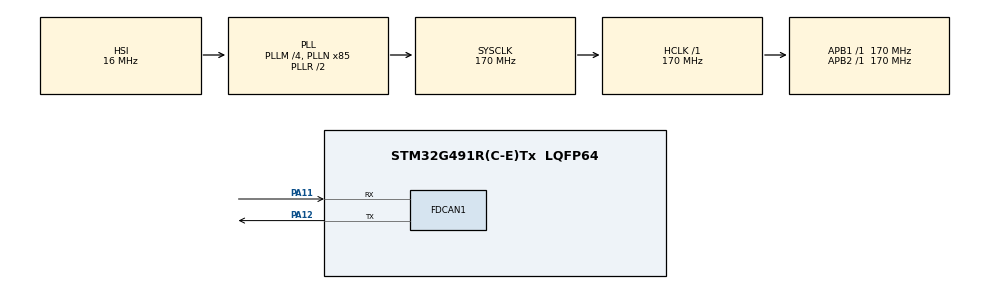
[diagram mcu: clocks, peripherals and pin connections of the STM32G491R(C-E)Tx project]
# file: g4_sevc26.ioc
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FDCAN1.AutoRetransmission=ENABLE
FDCAN1.CalculateBaudRateNominal=500000
FDCAN1.CalculateTimeBitNominal=2000
FDCAN1.CalculateTimeQuantumNominal=100.0
FDCAN1.FrameFormat=FDCAN_FRAME_CLASSIC
FDCAN1.NominalPrescaler=17
FDCAN1.NominalSyncJumpWidth=4
FDCAN1.NominalTimeSeg1=15
FDCAN1.NominalTimeSeg2=4
FDCAN1.StdFiltersNbr=1
Mcu.Family=STM32G4
Mcu.Name=STM32G491R(C-E)Tx
Mcu.Package=LQFP64
NVIC.FDCAN1_IT0_IRQn=true\:0\:0\:false\:false\:true\:true\:true\:true
NVIC.PriorityGroup=NVIC_PRIORITYGROUP_4
PA11.Mode=FDCAN_Activate
PA11.Signal=FDCAN1_RX
PA12.Mode=FDCAN_Activate
PA12.Signal=FDCAN1_TX
ProjectManager.HeapSize=0x200
ProjectManager.StackSize=0x400
ProjectManager.TargetToolchain=STM32CubeIDE
RCC.ADC12Freq_Value=170000000
RCC.ADC345Freq_Value=170000000
RCC.AHBFreq_Value=170000000
RCC.APB1Freq_Value=170000000
RCC.APB1TimFreq_Value=170000000
RCC.APB2Freq_Value=170000000
RCC.APB2TimFreq_Value=170000000
RCC.CortexFreq_Value=170000000
RCC.EXTERNAL_CLOCK_VALUE=12288000
RCC.FDCANCLockSelection=RCC_FDCANCLKSOURCE_PLL
RCC.HCLKFreq_Value=170000000
RCC.HSE_VALUE=8000000
RCC.HSI48_VALUE=48000000
RCC.HSI_VALUE=16000000
RCC.LSE_VALUE=32768
RCC.PLLM=RCC_PLLM_DIV4
RCC.PLLN=85
RCC.SYSCLKFreq_VALUE=170000000
RCC.SYSCLKSource=RCC_SYSCLKSOURCE_PLLCLK
RCC.VCOOutputFreq_Value=340000000
VP_SYS_VS_DBSignals.Mode=DisableDeadBatterySignals
board=custom

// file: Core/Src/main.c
/* USER CODE BEGIN Header */
/**
  ******************************************************************************
  * @file           : main.c
  * @brief          : Main program body - G4 CAN Transmitter
  ******************************************************************************
  */
/* USER CODE END Header */

#include "main.h"

FDCAN_HandleTypeDef hfdcan1;

/* USER CODE BEGIN PV */
volatile uint32_t tx_count = 0;
volatile uint32_t tx_error_count = 0;
volatile uint32_t tx_busy_count = 0;
volatile uint32_t tx_last_id = 0;
volatile uint8_t tx_data[8] = {0};

uint32_t last_tx_tick = 0;
uint8_t sequence = 0;
/* USER CODE END PV */

void SystemClock_Config(void);
static void MX_GPIO_Init(void);
static void MX_FDCAN1_Init(void);

/* USER CODE BEGIN PFP */
static void FDCAN_ConfigureTransmitter(void);
static void FDCAN_TransmitData(void);
/* USER CODE END PFP */

int main(void)
{
  HAL_Init();

  SystemClock_Config();

  MX_GPIO_Init();
  MX_FDCAN1_Init();

  /* USER CODE BEGIN 2 */

  FDCAN_ConfigureTransmitter();

  if (HAL_FDCAN_Start(&hfdcan1) != HAL_OK)
  {
    Error_Handler();
  }

  last_tx_tick = HAL_GetTick();

  /* USER CODE END 2 */

  while (1)
  {
    /* USER CODE BEGIN 3 */

    if ((HAL_GetTick() - last_tx_tick) >= 100U)
    {
      last_tx_tick = HAL_GetTick();
      FDCAN_TransmitData();
    }

    /* USER CODE END 3 */
  }
}

void SystemClock_Config(void)
{
  RCC_OscInitTypeDef RCC_OscInitStruct = {0};
  RCC_ClkInitTypeDef RCC_ClkInitStruct = {0};

  HAL_PWREx_ControlVoltageScaling(
      PWR_REGULATOR_VOLTAGE_SCALE1_BOOST);

  RCC_OscInitStruct.OscillatorType = RCC_OSCILLATORTYPE_HSI;
  RCC_OscInitStruct.HSIState = RCC_HSI_ON;
  RCC_OscInitStruct.HSICalibrationValue =
      RCC_HSICALIBRATION_DEFAULT;
  RCC_OscInitStruct.PLL.PLLState = RCC_PLL_ON;
  RCC_OscInitStruct.PLL.PLLSource = RCC_PLLSOURCE_HSI;
  RCC_OscInitStruct.PLL.PLLM = RCC_PLLM_DIV4;
  RCC_OscInitStruct.PLL.PLLN = 85;
  RCC_OscInitStruct.PLL.PLLP = RCC_PLLP_DIV2;
  RCC_OscInitStruct.PLL.PLLQ = RCC_PLLQ_DIV2;
  RCC_OscInitStruct.PLL.PLLR = RCC_PLLR_DIV2;

  if (HAL_RCC_OscConfig(&RCC_OscInitStruct) != HAL_OK)
  {
    Error_Handler();
  }

  RCC_ClkInitStruct.ClockType = RCC_CLOCKTYPE_HCLK |
                                RCC_CLOCKTYPE_SYSCLK |
                                RCC_CLOCKTYPE_PCLK1 |
                                RCC_CLOCKTYPE_PCLK2;
  RCC_ClkInitStruct.SYSCLKSource = RCC_SYSCLKSOURCE_PLLCLK;
  RCC_ClkInitStruct.AHBCLKDivider = RCC_SYSCLK_DIV1;
  RCC_ClkInitStruct.APB1CLKDivider = RCC_HCLK_DIV1;
  RCC_ClkInitStruct.APB2CLKDivider = RCC_HCLK_DIV1;

  if (HAL_RCC_ClockConfig(&RCC_ClkInitStruct,
                          FLASH_LATENCY_4) != HAL_OK)
  {
    Error_Handler();
  }
}

static void MX_FDCAN1_Init(void)
{
  hfdcan1.Instance = FDCAN1;
  hfdcan1.Init.ClockDivider = FDCAN_CLOCK_DIV1;
  hfdcan1.Init.FrameFormat = FDCAN_FRAME_CLASSIC;
  hfdcan1.Init.Mode = FDCAN_MODE_NORMAL;
  hfdcan1.Init.AutoRetransmission = ENABLE;
  hfdcan1.Init.TransmitPause = DISABLE;
  hfdcan1.Init.ProtocolException = DISABLE;

  /* 500 kbps, assuming a 170 MHz FDCAN kernel clock */
  hfdcan1.Init.NominalPrescaler = 17;
  hfdcan1.Init.NominalSyncJumpWidth = 4;
  hfdcan1.Init.NominalTimeSeg1 = 15;
  hfdcan1.Init.NominalTimeSeg2 = 4;

  hfdcan1.Init.DataPrescaler = 1;
  hfdcan1.Init.DataSyncJumpWidth = 1;
  hfdcan1.Init.DataTimeSeg1 = 1;
  hfdcan1.Init.DataTimeSeg2 = 1;

  hfdcan1.Init.StdFiltersNbr = 1;
  hfdcan1.Init.ExtFiltersNbr = 0;
  hfdcan1.Init.TxFifoQueueMode = FDCAN_TX_FIFO_OPERATION;

  if (HAL_FDCAN_Init(&hfdcan1) != HAL_OK)
  {
    Error_Handler();
  }
}

/**
  * @brief Configure G4 transmitter.
  */
static void FDCAN_ConfigureTransmitter(void)
{
  /* No receive filter is required for transmission. */
}

/**
  * @brief Transmit an 8-byte Classic CAN frame to the H7.
  *        Standard CAN ID: 0x100
  */
static void FDCAN_TransmitData(void)
{
  FDCAN_TxHeaderTypeDef txHeader;
  uint8_t data[8];

  /* Example test payload */
  data[0] = sequence++;
  data[1] = 0xA5;
  data[2] = 0x5A;
  data[3] = 0xAA;
  data[4] = 0x55;
  data[5] = 0x11;
  data[6] = 0x22;
  data[7] = 0x33;

  txHeader.Identifier = 0x100;
  txHeader.IdType = FDCAN_STANDARD_ID;
  txHeader.TxFrameType = FDCAN_DATA_FRAME;
  txHeader.DataLength = FDCAN_DLC_BYTES_8;
  txHeader.ErrorStateIndicator = FDCAN_ESI_ACTIVE;
  txHeader.BitRateSwitch = FDCAN_BRS_OFF;
  txHeader.FDFormat = FDCAN_CLASSIC_CAN;
  txHeader.TxEventFifoControl = FDCAN_NO_TX_EVENTS;
  txHeader.MessageMarker = 0;

  if (HAL_FDCAN_GetTxFifoFreeLevel(&hfdcan1) > 0U)
  {
    if (HAL_FDCAN_AddMessageToTxFifoQ(
            &hfdcan1, &txHeader, data) == HAL_OK)
    {
      tx_last_id = txHeader.Identifier;

      for (uint32_t i = 0; i < 8U; i++)
      {
        tx_data[i] = data[i];
      }

      tx_count++;
    }
    else
    {
      tx_error_count++;
    }
  }
  else
  {
    tx_busy_count++;
  }
}

static void MX_GPIO_Init(void)
{
  __HAL_RCC_GPIOA_CLK_ENABLE();
}

/**
  * @brief Error Handler
  */
void Error_Handler(void)
{
  __disable_irq();

  while (1)
  {
  }
}
